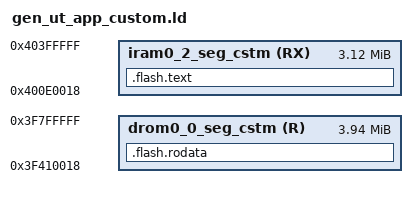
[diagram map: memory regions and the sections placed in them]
/*
Linker file used to link unit test app with non-standard flash mappings.
*/

MEMORY
{
  /* Even though the segment name is iram, it is actually mapped to flash
  */
  iram0_2_seg_cstm (RX) :                 org = 0x400D0018 + 0x10000, len = 0x330000-0x18 - 0x10000

  /*
    (0x18 offset above is a convenience for the app binary image generation. Flash cache has 64KB pages. The .bin file
    which is flashed to the chip has a 0x18 byte file header. Setting this offset makes it simple to meet the flash
    cache MMU's constraint that (paddr % 64KB == vaddr % 64KB).)
  */

  /* Flash mapped constant data */
  drom0_0_seg_cstm (R) :                  org = 0x3F400018 + 0x10000, len = 0x400000-0x18 - 0x10000
}

SECTIONS
{
  .flash.rodata :
  {
    _rodata_start = ABSOLUTE(.);
    *(.rodata)
    *(.rodata.*)
    *(.irom1.text) /* catch stray ICACHE_RODATA_ATTR */
    *(.gnu.linkonce.r.*)
    *(.rodata1)
    __XT_EXCEPTION_TABLE_ = ABSOLUTE(.);
    *(.xt_except_table)
    *(.gcc_except_table .gcc_except_table.*)
    *(.gnu.linkonce.e.*)
    *(.gnu.version_r)
    . = (. + 3) & ~ 3;
    __eh_frame = ABSOLUTE(.);
    KEEP(*(.eh_frame))
    . = (. + 7) & ~ 3;
    /*  C++ constructor and destructor tables

        Make a point of not including anything from crtbegin.o or crtend.o, as IDF doesn't use toolchain crt
      */
    __init_array_start = ABSOLUTE(.);
    KEEP (*(EXCLUDE_FILE (*crtend.* *crtbegin.*) .ctors .ctors.*))
    __init_array_end = ABSOLUTE(.);
    KEEP (*crtbegin.o(.dtors))
    KEEP (*(EXCLUDE_FILE (*crtend.o) .dtors))
    KEEP (*(SORT(.dtors.*)))
    KEEP (*(.dtors))
    /*  C++ exception handlers table:  */
    __XT_EXCEPTION_DESCS_ = ABSOLUTE(.);
    *(.xt_except_desc)
    *(.gnu.linkonce.h.*)
    __XT_EXCEPTION_DESCS_END__ = ABSOLUTE(.);
    *(.xt_except_desc_end)
    *(.dynamic)
    *(.gnu.version_d)
    _rodata_end = ABSOLUTE(.);
    /* Literals are also RO data. */
    _lit4_start = ABSOLUTE(.);
    *(*.lit4)
    *(.lit4.*)
    *(.gnu.linkonce.lit4.*)
    _lit4_end = ABSOLUTE(.);
    . = ALIGN(4);
    _thread_local_start = ABSOLUTE(.);
    *(.tdata)
    *(.tdata.*)
    *(.tbss)
    *(.tbss.*)
    _thread_local_end = ABSOLUTE(.);
    . = ALIGN(4);
  } >drom0_0_seg_cstm

  .flash.text :
  {
    _stext = .;
    _text_start = ABSOLUTE(.);
    *(.literal .text .literal.* .text.* .stub .gnu.warning .gnu.linkonce.literal.* .gnu.linkonce.t.*.literal .gnu.linkonce.t.*)
    *(.irom0.text) /* catch stray ICACHE_RODATA_ATTR */
    *(.fini.literal)
    *(.fini)
    *(.gnu.version)
    _text_end = ABSOLUTE(.);
    _etext = .;

    /* Similar to _iram_start, this symbol goes here so it is
       resolved by addr2line in preference to the first symbol in
       the flash.text segment.
    */
    _flash_cache_start = ABSOLUTE(0);
  } >iram0_2_seg_cstm
}
